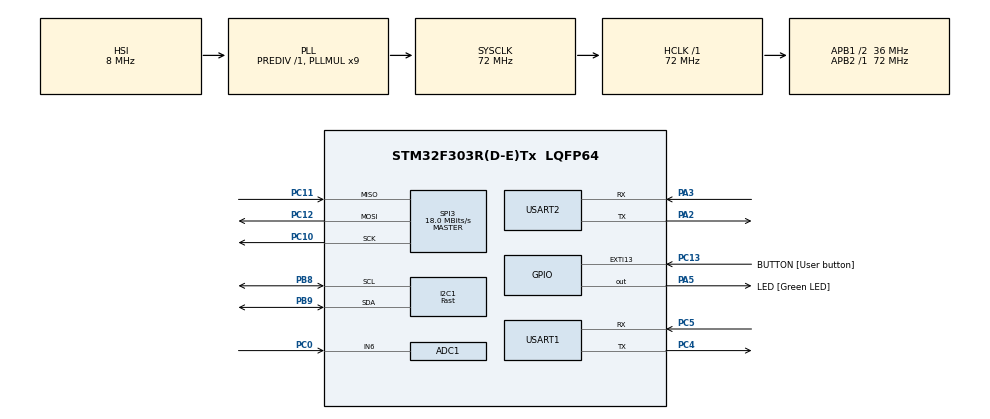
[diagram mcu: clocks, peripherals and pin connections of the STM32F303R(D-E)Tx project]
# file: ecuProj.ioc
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ADC1.Channel-0\#ChannelRegularConversion=ADC_CHANNEL_6
ADC1.NbrOfConversionFlag=1
ADC1.Offset-0\#ChannelRegularConversion=0
ADC1.OffsetNumber-0\#ChannelRegularConversion=ADC_OFFSET_NONE
ADC1.Rank-0\#ChannelRegularConversion=1
ADC1.SamplingTime-0\#ChannelRegularConversion=ADC_SAMPLETIME_1CYCLE_5
ADC1.master=1
I2C1.I2C_Speed_Mode=I2C_Fast
I2C1.Timing=0x00702681
Mcu.Family=STM32F3
Mcu.Name=STM32F303R(D-E)Tx
Mcu.Package=LQFP64
NVIC.ADC1_2_IRQn=true\:0\:0\:false\:false\:true\:true\:true\:true
NVIC.EXTI15_10_IRQn=true\:0\:0\:false\:false\:true\:true\:true\:true
NVIC.I2C1_EV_IRQn=true\:0\:0\:false\:false\:true\:true\:true\:true
NVIC.PriorityGroup=NVIC_PRIORITYGROUP_4
NVIC.SPI3_IRQn=true\:0\:0\:false\:false\:true\:true\:true\:true
NVIC.TIM3_IRQn=true\:0\:0\:false\:false\:true\:true\:true\:true
NVIC.USART1_IRQn=true\:0\:0\:false\:false\:true\:true\:true\:true
NVIC.USART2_IRQn=true\:0\:0\:false\:false\:true\:true\:true\:true
PA2.Mode=Asynchronous
PA2.Signal=USART2_TX
PA3.Mode=Asynchronous
PA3.Signal=USART2_RX
PA5.GPIO_Label=LED [Green LED]
PA5.Signal=GPIO_Output
PB8.Mode=I2C
PB8.Signal=I2C1_SCL
PB9.Mode=I2C
PB9.Signal=I2C1_SDA
PC0.Signal=ADCx_IN6
PC10.Mode=Full_Duplex_Master
PC10.Signal=SPI3_SCK
PC11.Mode=Full_Duplex_Master
PC11.Signal=SPI3_MISO
PC12.Mode=Full_Duplex_Master
PC12.Signal=SPI3_MOSI
PC13.GPIO_Label=BUTTON [User button]
PC13.Signal=GPXTI13
PC4.Mode=Asynchronous
PC4.Signal=USART1_TX
PC5.Mode=Asynchronous
PC5.Signal=USART1_RX
ProjectManager.HeapSize=0x200
ProjectManager.StackSize=0x400
ProjectManager.TargetToolchain=STM32CubeIDE
RCC.AHBFreq_Value=72000000
RCC.APB1CLKDivider=RCC_HCLK_DIV2
RCC.APB1Freq_Value=36000000
RCC.APB1TimFreq_Value=72000000
RCC.APB2Freq_Value=72000000
RCC.APB2TimFreq_Value=72000000
RCC.CortexFreq_Value=72000000
RCC.HCLKFreq_Value=72000000
RCC.HSE_VALUE=8000000
RCC.HSI_VALUE=8000000
RCC.I2c1ClockSelection=RCC_I2C1CLKSOURCE_SYSCLK
RCC.LSE_VALUE=32768
RCC.PLLMUL=RCC_PLL_MUL9
RCC.SYSCLKFreq_VALUE=72000000
RCC.SYSCLKSourceVirtual=RCC_SYSCLKSOURCE_PLLCLK
RCC.USBFreq_Value=72000000
SH.ADCx_IN6.0=ADC1_IN6,IN6-Single-Ended
SPI3.CalculateBaudRate=18.0 MBits/s
SPI3.Direction=SPI_DIRECTION_2LINES
SPI3.Mode=SPI_MODE_MASTER
SPI3.VirtualType=VM_MASTER
TIM3.AutoReloadPreload=TIM_AUTORELOAD_PRELOAD_ENABLE
TIM3.Period=7200
TIM3.Prescaler=10000
USART1.VirtualMode-Asynchronous=VM_ASYNC
USART2.VirtualMode-Asynchronous=VM_ASYNC
VP_TIM3_VS_ClockSourceINT.Mode=Internal
board=custom

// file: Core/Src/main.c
/* USER CODE BEGIN Header */
/**
  ******************************************************************************
  * @file           : main.c
  * @brief          : Main program body
  ******************************************************************************
  * @attention
  *
  * Copyright (c) 2022 STMicroelectronics.
  * All rights reserved.
  *
  * This software is licensed under terms that can be found in the LICENSE file
  * in the root directory of this software component.
  * If no LICENSE file comes with this software, it is provided AS-IS.
  *
  ******************************************************************************
  */
/* USER CODE END Header */
#include "main.h"

ADC_HandleTypeDef hadc1;

I2C_HandleTypeDef hi2c1;

SPI_HandleTypeDef hspi3;

TIM_HandleTypeDef htim3;

UART_HandleTypeDef huart1;
UART_HandleTypeDef huart2;

/* USER CODE BEGIN PV */
static uint8_t led_toggle = 0;
uint32_t tim3_count = 0u;
/* USER CODE END PV */

void SystemClock_Config(void);
static void MX_GPIO_Init(void);
static void MX_ADC1_Init(void);
static void MX_I2C1_Init(void);
static void MX_SPI3_Init(void);
static void MX_USART1_UART_Init(void);
static void MX_USART2_UART_Init(void);
static void MX_TIM3_Init(void);

int main(void)
{

  /* MCU Configuration--------------------------------------------------------*/

  /* Reset of all peripherals, Initializes the Flash interface and the Systick. */
  HAL_Init();

  /* Configure the system clock */
  SystemClock_Config();

  /* Initialize all configured peripherals */
  MX_GPIO_Init();
  MX_ADC1_Init();
  MX_I2C1_Init();
  MX_SPI3_Init();
  MX_USART1_UART_Init();
  MX_USART2_UART_Init();
  MX_TIM3_Init();
  /* USER CODE BEGIN 2 */
  HAL_TIM_Base_Start_IT(&htim3);
  /* USER CODE END 2 */

  /* Infinite loop */
  /* USER CODE BEGIN WHILE */
  while (1)
  {
	  HAL_Delay(500);
	  if(0u != led_toggle)
	  {
		  HAL_GPIO_TogglePin(LED_GPIO_Port, LED_Pin);
	  }
    /* USER CODE END WHILE */

  }
}

void SystemClock_Config(void)
{
  RCC_OscInitTypeDef RCC_OscInitStruct = {0};
  RCC_ClkInitTypeDef RCC_ClkInitStruct = {0};
  RCC_PeriphCLKInitTypeDef PeriphClkInit = {0};

  /** Initializes the RCC Oscillators according to the specified parameters
  * in the RCC_OscInitTypeDef structure.
  */
  RCC_OscInitStruct.OscillatorType = RCC_OSCILLATORTYPE_HSI;
  RCC_OscInitStruct.HSIState = RCC_HSI_ON;
  RCC_OscInitStruct.HSICalibrationValue = RCC_HSICALIBRATION_DEFAULT;
  RCC_OscInitStruct.PLL.PLLState = RCC_PLL_ON;
  RCC_OscInitStruct.PLL.PLLSource = RCC_PLLSOURCE_HSI;
  RCC_OscInitStruct.PLL.PLLMUL = RCC_PLL_MUL9;
  RCC_OscInitStruct.PLL.PREDIV = RCC_PREDIV_DIV1;
  if (HAL_RCC_OscConfig(&RCC_OscInitStruct) != HAL_OK)
  {
    Error_Handler();
  }

  /** Initializes the CPU, AHB and APB buses clocks
  */
  RCC_ClkInitStruct.ClockType = RCC_CLOCKTYPE_HCLK|RCC_CLOCKTYPE_SYSCLK
                              |RCC_CLOCKTYPE_PCLK1|RCC_CLOCKTYPE_PCLK2;
  RCC_ClkInitStruct.SYSCLKSource = RCC_SYSCLKSOURCE_PLLCLK;
  RCC_ClkInitStruct.AHBCLKDivider = RCC_SYSCLK_DIV1;
  RCC_ClkInitStruct.APB1CLKDivider = RCC_HCLK_DIV2;
  RCC_ClkInitStruct.APB2CLKDivider = RCC_HCLK_DIV1;

  if (HAL_RCC_ClockConfig(&RCC_ClkInitStruct, FLASH_LATENCY_2) != HAL_OK)
  {
    Error_Handler();
  }
  PeriphClkInit.PeriphClockSelection = RCC_PERIPHCLK_USART1|RCC_PERIPHCLK_USART2
                              |RCC_PERIPHCLK_I2C1|RCC_PERIPHCLK_ADC12
                              |RCC_PERIPHCLK_TIM34;
  PeriphClkInit.Usart1ClockSelection = RCC_USART1CLKSOURCE_PCLK2;
  PeriphClkInit.Usart2ClockSelection = RCC_USART2CLKSOURCE_PCLK1;
  PeriphClkInit.Adc12ClockSelection = RCC_ADC12PLLCLK_DIV1;
  PeriphClkInit.I2c1ClockSelection = RCC_I2C1CLKSOURCE_SYSCLK;
  PeriphClkInit.Tim34ClockSelection = RCC_TIM34CLK_HCLK;
  if (HAL_RCCEx_PeriphCLKConfig(&PeriphClkInit) != HAL_OK)
  {
    Error_Handler();
  }
}

static void MX_ADC1_Init(void)
{

  ADC_MultiModeTypeDef multimode = {0};
  ADC_ChannelConfTypeDef sConfig = {0};

  /** Common config
  */
  hadc1.Instance = ADC1;
  hadc1.Init.ClockPrescaler = ADC_CLOCK_ASYNC_DIV1;
  hadc1.Init.Resolution = ADC_RESOLUTION_12B;
  hadc1.Init.ScanConvMode = ADC_SCAN_DISABLE;
  hadc1.Init.ContinuousConvMode = DISABLE;
  hadc1.Init.DiscontinuousConvMode = DISABLE;
  hadc1.Init.ExternalTrigConvEdge = ADC_EXTERNALTRIGCONVEDGE_NONE;
  hadc1.Init.ExternalTrigConv = ADC_SOFTWARE_START;
  hadc1.Init.DataAlign = ADC_DATAALIGN_RIGHT;
  hadc1.Init.NbrOfConversion = 1;
  hadc1.Init.DMAContinuousRequests = DISABLE;
  hadc1.Init.EOCSelection = ADC_EOC_SINGLE_CONV;
  hadc1.Init.LowPowerAutoWait = DISABLE;
  hadc1.Init.Overrun = ADC_OVR_DATA_OVERWRITTEN;
  if (HAL_ADC_Init(&hadc1) != HAL_OK)
  {
    Error_Handler();
  }

  /** Configure the ADC multi-mode
  */
  multimode.Mode = ADC_MODE_INDEPENDENT;
  if (HAL_ADCEx_MultiModeConfigChannel(&hadc1, &multimode) != HAL_OK)
  {
    Error_Handler();
  }

  /** Configure Regular Channel
  */
  sConfig.Channel = ADC_CHANNEL_6;
  sConfig.Rank = ADC_REGULAR_RANK_1;
  sConfig.SingleDiff = ADC_SINGLE_ENDED;
  sConfig.SamplingTime = ADC_SAMPLETIME_1CYCLE_5;
  sConfig.OffsetNumber = ADC_OFFSET_NONE;
  sConfig.Offset = 0;
  if (HAL_ADC_ConfigChannel(&hadc1, &sConfig) != HAL_OK)
  {
    Error_Handler();
  }

}

static void MX_I2C1_Init(void)
{

  hi2c1.Instance = I2C1;
  hi2c1.Init.Timing = 0x00702681;
  hi2c1.Init.OwnAddress1 = 0;
  hi2c1.Init.AddressingMode = I2C_ADDRESSINGMODE_7BIT;
  hi2c1.Init.DualAddressMode = I2C_DUALADDRESS_DISABLE;
  hi2c1.Init.OwnAddress2 = 0;
  hi2c1.Init.OwnAddress2Masks = I2C_OA2_NOMASK;
  hi2c1.Init.GeneralCallMode = I2C_GENERALCALL_DISABLE;
  hi2c1.Init.NoStretchMode = I2C_NOSTRETCH_DISABLE;
  if (HAL_I2C_Init(&hi2c1) != HAL_OK)
  {
    Error_Handler();
  }

  /** Configure Analogue filter
  */
  if (HAL_I2CEx_ConfigAnalogFilter(&hi2c1, I2C_ANALOGFILTER_ENABLE) != HAL_OK)
  {
    Error_Handler();
  }

  /** Configure Digital filter
  */
  if (HAL_I2CEx_ConfigDigitalFilter(&hi2c1, 0) != HAL_OK)
  {
    Error_Handler();
  }

}

static void MX_SPI3_Init(void)
{

  /* SPI3 parameter configuration*/
  hspi3.Instance = SPI3;
  hspi3.Init.Mode = SPI_MODE_MASTER;
  hspi3.Init.Direction = SPI_DIRECTION_2LINES;
  hspi3.Init.DataSize = SPI_DATASIZE_4BIT;
  hspi3.Init.CLKPolarity = SPI_POLARITY_LOW;
  hspi3.Init.CLKPhase = SPI_PHASE_1EDGE;
  hspi3.Init.NSS = SPI_NSS_SOFT;
  hspi3.Init.BaudRatePrescaler = SPI_BAUDRATEPRESCALER_2;
  hspi3.Init.FirstBit = SPI_FIRSTBIT_MSB;
  hspi3.Init.TIMode = SPI_TIMODE_DISABLE;
  hspi3.Init.CRCCalculation = SPI_CRCCALCULATION_DISABLE;
  hspi3.Init.CRCPolynomial = 7;
  hspi3.Init.CRCLength = SPI_CRC_LENGTH_DATASIZE;
  hspi3.Init.NSSPMode = SPI_NSS_PULSE_ENABLE;
  if (HAL_SPI_Init(&hspi3) != HAL_OK)
  {
    Error_Handler();
  }

}

static void MX_TIM3_Init(void)
{

  TIM_ClockConfigTypeDef sClockSourceConfig = {0};
  TIM_MasterConfigTypeDef sMasterConfig = {0};

  htim3.Instance = TIM3;
  htim3.Init.Prescaler = 10000;
  htim3.Init.CounterMode = TIM_COUNTERMODE_UP;
  htim3.Init.Period = 7200;
  htim3.Init.ClockDivision = TIM_CLOCKDIVISION_DIV1;
  htim3.Init.AutoReloadPreload = TIM_AUTORELOAD_PRELOAD_ENABLE;
  if (HAL_TIM_Base_Init(&htim3) != HAL_OK)
  {
    Error_Handler();
  }
  sClockSourceConfig.ClockSource = TIM_CLOCKSOURCE_INTERNAL;
  if (HAL_TIM_ConfigClockSource(&htim3, &sClockSourceConfig) != HAL_OK)
  {
    Error_Handler();
  }
  sMasterConfig.MasterOutputTrigger = TIM_TRGO_RESET;
  sMasterConfig.MasterSlaveMode = TIM_MASTERSLAVEMODE_DISABLE;
  if (HAL_TIMEx_MasterConfigSynchronization(&htim3, &sMasterConfig) != HAL_OK)
  {
    Error_Handler();
  }

}

static void MX_USART1_UART_Init(void)
{

  huart1.Instance = USART1;
  huart1.Init.BaudRate = 38400;
  huart1.Init.WordLength = UART_WORDLENGTH_8B;
  huart1.Init.StopBits = UART_STOPBITS_1;
  huart1.Init.Parity = UART_PARITY_NONE;
  huart1.Init.Mode = UART_MODE_TX_RX;
  huart1.Init.HwFlowCtl = UART_HWCONTROL_NONE;
  huart1.Init.OverSampling = UART_OVERSAMPLING_16;
  huart1.Init.OneBitSampling = UART_ONE_BIT_SAMPLE_DISABLE;
  huart1.AdvancedInit.AdvFeatureInit = UART_ADVFEATURE_NO_INIT;
  if (HAL_UART_Init(&huart1) != HAL_OK)
  {
    Error_Handler();
  }

}

static void MX_USART2_UART_Init(void)
{

  huart2.Instance = USART2;
  huart2.Init.BaudRate = 38400;
  huart2.Init.WordLength = UART_WORDLENGTH_8B;
  huart2.Init.StopBits = UART_STOPBITS_1;
  huart2.Init.Parity = UART_PARITY_NONE;
  huart2.Init.Mode = UART_MODE_TX_RX;
  huart2.Init.HwFlowCtl = UART_HWCONTROL_NONE;
  huart2.Init.OverSampling = UART_OVERSAMPLING_16;
  huart2.Init.OneBitSampling = UART_ONE_BIT_SAMPLE_DISABLE;
  huart2.AdvancedInit.AdvFeatureInit = UART_ADVFEATURE_NO_INIT;
  if (HAL_UART_Init(&huart2) != HAL_OK)
  {
    Error_Handler();
  }

}

static void MX_GPIO_Init(void)
{
  GPIO_InitTypeDef GPIO_InitStruct = {0};

  /* GPIO Ports Clock Enable */
  __HAL_RCC_GPIOC_CLK_ENABLE();
  __HAL_RCC_GPIOA_CLK_ENABLE();
  __HAL_RCC_GPIOB_CLK_ENABLE();

  /*Configure GPIO pin Output Level */
  HAL_GPIO_WritePin(LED_GPIO_Port, LED_Pin, GPIO_PIN_RESET);

  /*Configure GPIO pin : BUTTON_Pin */
  GPIO_InitStruct.Pin = BUTTON_Pin;
  GPIO_InitStruct.Mode = GPIO_MODE_IT_RISING;
  GPIO_InitStruct.Pull = GPIO_NOPULL;
  HAL_GPIO_Init(BUTTON_GPIO_Port, &GPIO_InitStruct);

  /*Configure GPIO pin : LED_Pin */
  GPIO_InitStruct.Pin = LED_Pin;
  GPIO_InitStruct.Mode = GPIO_MODE_OUTPUT_PP;
  GPIO_InitStruct.Pull = GPIO_NOPULL;
  GPIO_InitStruct.Speed = GPIO_SPEED_FREQ_LOW;
  HAL_GPIO_Init(LED_GPIO_Port, &GPIO_InitStruct);

  /* EXTI interrupt init*/
  HAL_NVIC_SetPriority(EXTI15_10_IRQn, 0, 0);
  HAL_NVIC_EnableIRQ(EXTI15_10_IRQn);

}

/* USER CODE BEGIN 4 */
void HAL_GPIO_EXTI_Callback(uint16_t GPIO_Pin)
{
	if(GPIO_Pin == BUTTON_Pin)
	{
		if(led_toggle == 0u)
		{
			led_toggle = 1u;
		}
		else
		{
			led_toggle = 0u;
		}
	}
}

void HAL_TIM_PeriodElapsedCallback(TIM_HandleTypeDef* htim)
{
	tim3_count++;
}
/* USER CODE END 4 */

void Error_Handler(void)
{
  __disable_irq();
  while (1)
  {
  }
}
